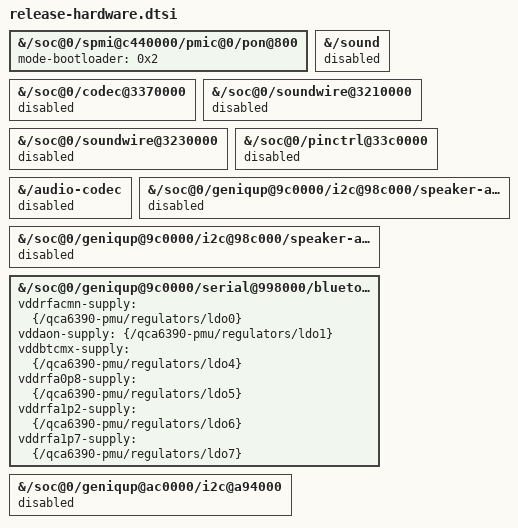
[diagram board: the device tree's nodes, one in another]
// SPDX-License-Identifier: BSD-3-Clause

/* Match the Umi ABL Fastboot reboot reason used by the board sources. */
&{/soc@0/spmi@c440000/pmic@0/pon@800} {
	mode-bootloader = <0x2>;
};

/* The donor disables the ADSP that provides LPASS clocks. Keep its
 * dependent sound card, VA macro and RX/TX SoundWire controllers offline
 * until the Umi audio chain is supported.
 */
&{/sound} {
	status = "disabled";
};

&{/soc@0/codec@3370000} {
	status = "disabled";
};

&{/soc@0/soundwire@3210000} {
	status = "disabled";
};

&{/soc@0/soundwire@3230000} {
	status = "disabled";
};

/* The LPI controller itself cannot probe without the same ADSP clocks. */
&{/soc@0/pinctrl@33c0000} {
	status = "disabled";
};

/* The donor also leaves the WCD938x codec and both CS35L41 speaker
 * amplifiers enabled.  They are part of the same unsupported audio chain:
 * without a sound card they only log missing supplies, MBHC thresholds and
 * the shared-reset warning.  Keep them from probing in release images.
 */
&{/audio-codec} {
	status = "disabled";
};

&{/soc@0/geniqup@9c0000/i2c@98c000/speaker-amp@40} {
	status = "disabled";
};

&{/soc@0/geniqup@9c0000/i2c@98c000/speaker-amp@42} {
	status = "disabled";
};

/* The PMU already owns BT_EN. Link the Bluetooth consumer to the exact
 * donor PMU supplies so hci_qca can find its power sequencer, without
 * taking the PMU's GPIO pinctrl state a second time.
 */
&{/soc@0/geniqup@9c0000/serial@998000/bluetooth} {
	/delete-property/ pinctrl-names;
	/delete-property/ pinctrl-0;
	/delete-property/ enable-gpios;
	/delete-property/ swctrl-gpios;
	vddrfacmn-supply = <&{/qca6390-pmu/regulators/ldo0}>;
	vddaon-supply = <&{/qca6390-pmu/regulators/ldo1}>;
	vddbtcmx-supply = <&{/qca6390-pmu/regulators/ldo4}>;
	vddrfa0p8-supply = <&{/qca6390-pmu/regulators/ldo5}>;
	vddrfa1p2-supply = <&{/qca6390-pmu/regulators/ldo6}>;
	vddrfa1p7-supply = <&{/qca6390-pmu/regulators/ldo7}>;
};

/* This GPI-only serial engine's sole client is the unsupported FTS
 * touchscreen. Leave the shared DMA controller and other I2C buses alone.
 */
&{/soc@0/geniqup@ac0000/i2c@a94000} {
	status = "disabled";
};
